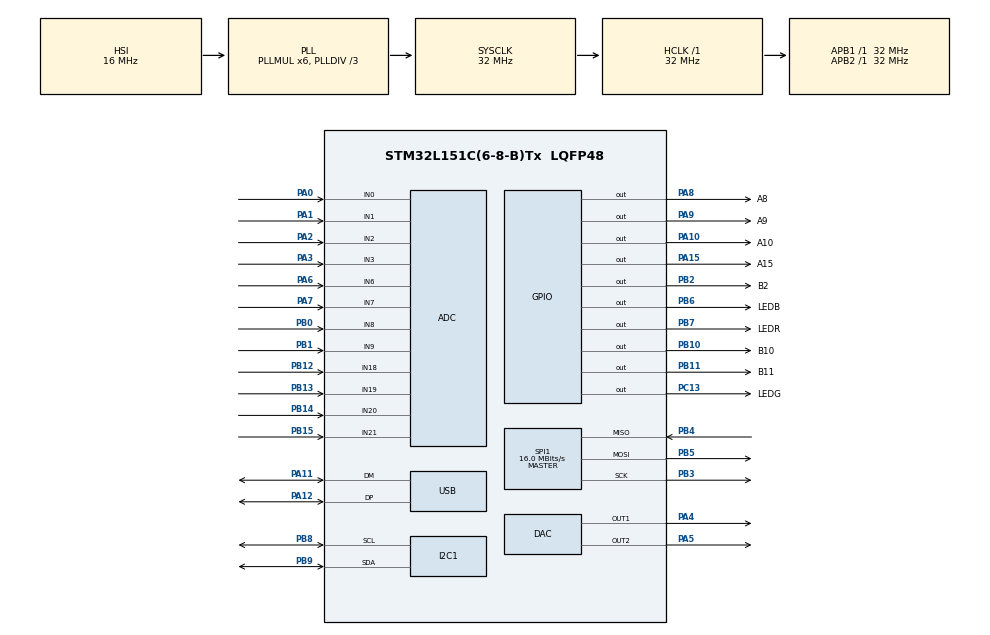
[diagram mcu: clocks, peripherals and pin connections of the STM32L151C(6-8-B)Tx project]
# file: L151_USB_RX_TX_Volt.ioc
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ADC.Channel-0\#ChannelRegularConversion=ADC_CHANNEL_VREFINT
ADC.Channel-1\#ChannelRegularConversion=ADC_CHANNEL_TEMPSENSOR
ADC.Channel-10\#ChannelRegularConversion=ADC_CHANNEL_18
ADC.Channel-11\#ChannelRegularConversion=ADC_CHANNEL_19
ADC.Channel-12\#ChannelRegularConversion=ADC_CHANNEL_20
ADC.Channel-13\#ChannelRegularConversion=ADC_CHANNEL_21
ADC.Channel-2\#ChannelRegularConversion=ADC_CHANNEL_0
ADC.Channel-3\#ChannelRegularConversion=ADC_CHANNEL_1
ADC.Channel-4\#ChannelRegularConversion=ADC_CHANNEL_2
ADC.Channel-5\#ChannelRegularConversion=ADC_CHANNEL_3
ADC.Channel-6\#ChannelRegularConversion=ADC_CHANNEL_6
ADC.Channel-7\#ChannelRegularConversion=ADC_CHANNEL_7
ADC.Channel-8\#ChannelRegularConversion=ADC_CHANNEL_8
ADC.Channel-9\#ChannelRegularConversion=ADC_CHANNEL_9
ADC.ClockPrescaler=ADC_CLOCK_ASYNC_DIV4
ADC.ContinuousConvMode=ENABLE
ADC.DMAContinuousRequests=ENABLE
ADC.NbrOfConversion=14
ADC.NbrOfConversionFlag=1
ADC.Rank-0\#ChannelRegularConversion=1
ADC.Rank-1\#ChannelRegularConversion=2
ADC.Rank-10\#ChannelRegularConversion=11
ADC.Rank-11\#ChannelRegularConversion=12
ADC.Rank-12\#ChannelRegularConversion=13
ADC.Rank-13\#ChannelRegularConversion=14
ADC.Rank-2\#ChannelRegularConversion=3
ADC.Rank-3\#ChannelRegularConversion=4
ADC.Rank-4\#ChannelRegularConversion=5
ADC.Rank-5\#ChannelRegularConversion=6
ADC.Rank-6\#ChannelRegularConversion=7
ADC.Rank-7\#ChannelRegularConversion=8
ADC.Rank-8\#ChannelRegularConversion=9
ADC.Rank-9\#ChannelRegularConversion=10
ADC.SamplingTime-0\#ChannelRegularConversion=ADC_SAMPLETIME_384CYCLES
ADC.SamplingTime-1\#ChannelRegularConversion=ADC_SAMPLETIME_384CYCLES
ADC.SamplingTime-10\#ChannelRegularConversion=ADC_SAMPLETIME_384CYCLES
ADC.SamplingTime-11\#ChannelRegularConversion=ADC_SAMPLETIME_384CYCLES
ADC.SamplingTime-12\#ChannelRegularConversion=ADC_SAMPLETIME_384CYCLES
ADC.SamplingTime-13\#ChannelRegularConversion=ADC_SAMPLETIME_384CYCLES
ADC.SamplingTime-2\#ChannelRegularConversion=ADC_SAMPLETIME_384CYCLES
ADC.SamplingTime-3\#ChannelRegularConversion=ADC_SAMPLETIME_384CYCLES
ADC.SamplingTime-4\#ChannelRegularConversion=ADC_SAMPLETIME_384CYCLES
ADC.SamplingTime-5\#ChannelRegularConversion=ADC_SAMPLETIME_384CYCLES
ADC.SamplingTime-6\#ChannelRegularConversion=ADC_SAMPLETIME_384CYCLES
ADC.SamplingTime-7\#ChannelRegularConversion=ADC_SAMPLETIME_384CYCLES
ADC.SamplingTime-8\#ChannelRegularConversion=ADC_SAMPLETIME_384CYCLES
ADC.SamplingTime-9\#ChannelRegularConversion=ADC_SAMPLETIME_384CYCLES
ADC.ScanConvMode=ADC_SCAN_ENABLE
Dma.ADC.0.Direction=DMA_PERIPH_TO_MEMORY
Dma.ADC.0.Instance=DMA1_Channel1
Dma.ADC.0.MemDataAlignment=DMA_MDATAALIGN_HALFWORD
Dma.ADC.0.MemInc=DMA_MINC_ENABLE
Dma.ADC.0.Mode=DMA_CIRCULAR
Dma.ADC.0.PeriphDataAlignment=DMA_PDATAALIGN_HALFWORD
Dma.ADC.0.PeriphInc=DMA_PINC_DISABLE
Dma.ADC.0.Priority=DMA_PRIORITY_LOW
Dma.Request0=ADC
Mcu.Family=STM32L1
Mcu.Name=STM32L151C(6-8-B)Tx
Mcu.Package=LQFP48
NVIC.DMA1_Channel1_IRQn=true\:0\:0\:false\:false\:true\:false\:true\:true
NVIC.PriorityGroup=NVIC_PRIORITYGROUP_4
NVIC.USB_LP_IRQn=true\:0\:0\:false\:false\:true\:false\:true\:true
PA0-WKUP1.Mode=IN0
PA0-WKUP1.Signal=ADC_IN0
PA1.Mode=IN1
PA1.Signal=ADC_IN1
PA10.GPIO_Label=A10
PA10.Signal=GPIO_Output
PA11.Mode=Device
PA11.Signal=USB_DM
PA12.Mode=Device
PA12.Signal=USB_DP
PA13.Mode=Serial_Wire
PA13.Signal=SYS_JTMS-SWDIO
PA14.Mode=Serial_Wire
PA14.Signal=SYS_JTCK-SWCLK
PA15.GPIO_Label=A15
PA15.Signal=GPIO_Output
PA2.Mode=IN2
PA2.Signal=ADC_IN2
PA3.Mode=IN3
PA3.Signal=ADC_IN3
PA4.Signal=COMP_DAC1_group
PA5.Signal=COMP_DAC2_group
PA6.Mode=IN6
PA6.Signal=ADC_IN6
PA7.Mode=IN7
PA7.Signal=ADC_IN7
PA8.GPIO_Label=A8
PA8.Signal=GPIO_Output
PA9.GPIO_Label=A9
PA9.Signal=GPIO_Output
PB0.Mode=IN8
PB0.Signal=ADC_IN8
PB1.Mode=IN9
PB1.Signal=ADC_IN9
PB10.GPIO_Label=B10
PB10.Signal=GPIO_Output
PB11.GPIO_Label=B11
PB11.Signal=GPIO_Output
PB12.Mode=IN18
PB12.Signal=ADC_IN18
PB13.Mode=IN19
PB13.Signal=ADC_IN19
PB14.Mode=IN20
PB14.Signal=ADC_IN20
PB15.Mode=IN21
PB15.Signal=ADC_IN21
PB2.GPIO_Label=B2
PB2.Signal=GPIO_Output
PB3.Mode=Full_Duplex_Master
PB3.Signal=SPI1_SCK
PB4.Mode=Full_Duplex_Master
PB4.Signal=SPI1_MISO
PB5.Mode=Full_Duplex_Master
PB5.Signal=SPI1_MOSI
PB6.GPIO_Label=LEDB
PB6.Signal=GPIO_Output
PB7.GPIO_Label=LEDR
PB7.Signal=GPIO_Output
PB8.Mode=I2C
PB8.Signal=I2C1_SCL
PB9.Mode=I2C
PB9.Signal=I2C1_SDA
PC13-WKUP2.GPIO_Label=LEDG
PC13-WKUP2.Signal=GPIO_Output
ProjectManager.HeapSize=0x200
ProjectManager.StackSize=0x400
ProjectManager.TargetToolchain=STM32CubeIDE
RCC.48MHZClocksFreq_Value=48000000
RCC.AHBFreq_Value=32000000
RCC.APB1Freq_Value=32000000
RCC.APB1TimFreq_Value=32000000
RCC.APB2Freq_Value=32000000
RCC.APB2TimFreq_Value=32000000
RCC.HCLKFreq_Value=32000000
RCC.HSE_VALUE=12000000
RCC.HSI_VALUE=16000000
RCC.LSE_VALUE=32768
RCC.MSI_VALUE=2097000
RCC.PLLDIV=RCC_PLL_DIV3
RCC.PLLMUL=RCC_PLL_MUL6
RCC.PLLSource=RCC_PLLSOURCE_HSI
RCC.PLLSourceVirtualString=RCC_PLLSOURCE_HSI
RCC.SYSCLKFreq_VALUE=32000000
RCC.SYSCLKSource=RCC_SYSCLKSOURCE_PLLCLK
RCC.VCOOutputFreq_Value=96000000
SH.COMP_DAC1_group.0=DAC_OUT1,DAC_OUT1
SH.COMP_DAC2_group.0=DAC_OUT2,DAC_OUT2
SPI1.CalculateBaudRate=16.0 MBits/s
SPI1.Direction=SPI_DIRECTION_2LINES
SPI1.Mode=SPI_MODE_MASTER
SPI1.VirtualType=VM_MASTER
USB_DEVICE.CLASS_NAME_FS=CDC
USB_DEVICE.VirtualMode=Cdc
USB_DEVICE.VirtualModeFS=Cdc_FS
VP_ADC_TempSens_Input.Mode=IN-TempSens
VP_ADC_Vref_Input.Mode=IN-Vrefint
VP_USB_DEVICE_VS_USB_DEVICE_CDC_FS.Mode=CDC_FS
board=custom

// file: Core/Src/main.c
/* USER CODE BEGIN Header */
/**
  ******************************************************************************
  * @file           : main.c
  * @brief          : Main program body
  ******************************************************************************
  * @attention
  *
  * Copyright (c) 2023 STMicroelectronics.
  * All rights reserved.
  *
  * This software is licensed under terms that can be found in the LICENSE file
  * in the root directory of this software component.
  * If no LICENSE file comes with this software, it is provided AS-IS.
  *
  ******************************************************************************
  */
/* USER CODE END Header */
#include "main.h"
#include "adc.h"
#include "dac.h"
#include "dma.h"
#include "i2c.h"
#include "spi.h"
#include "usb_device.h"
#include "gpio.h"

/* USER CODE BEGIN Includes */
#include "kernel.h"
/* USER CODE END Includes */

void SystemClock_Config(void);

int main(void)
{

  /* MCU Configuration--------------------------------------------------------*/

  /* Reset of all peripherals, Initializes the Flash interface and the Systick. */
  HAL_Init();

  /* Configure the system clock */
  SystemClock_Config();

  /* Initialize all configured peripherals */
  MX_GPIO_Init();
  MX_DMA_Init();
  MX_ADC_Init();
  MX_USB_DEVICE_Init();
  MX_DAC_Init();
  MX_I2C1_Init();
  MX_SPI1_Init();

  /* Infinite loop */
  /* USER CODE BEGIN WHILE */
  while (1)
  {
	  kernel_main();
    /* USER CODE END WHILE */

  }
}

void SystemClock_Config(void)
{
  RCC_OscInitTypeDef RCC_OscInitStruct = {0};
  RCC_ClkInitTypeDef RCC_ClkInitStruct = {0};

  /** Configure the main internal regulator output voltage
  */
  __HAL_PWR_VOLTAGESCALING_CONFIG(PWR_REGULATOR_VOLTAGE_SCALE1);

  /** Initializes the RCC Oscillators according to the specified parameters
  * in the RCC_OscInitTypeDef structure.
  */
  RCC_OscInitStruct.OscillatorType = RCC_OSCILLATORTYPE_HSI;
  RCC_OscInitStruct.HSIState = RCC_HSI_ON;
  RCC_OscInitStruct.HSICalibrationValue = RCC_HSICALIBRATION_DEFAULT;
  RCC_OscInitStruct.PLL.PLLState = RCC_PLL_ON;
  RCC_OscInitStruct.PLL.PLLSource = RCC_PLLSOURCE_HSI;
  RCC_OscInitStruct.PLL.PLLMUL = RCC_PLL_MUL6;
  RCC_OscInitStruct.PLL.PLLDIV = RCC_PLL_DIV3;
  if (HAL_RCC_OscConfig(&RCC_OscInitStruct) != HAL_OK)
  {
    Error_Handler();
  }

  /** Initializes the CPU, AHB and APB buses clocks
  */
  RCC_ClkInitStruct.ClockType = RCC_CLOCKTYPE_HCLK|RCC_CLOCKTYPE_SYSCLK
                              |RCC_CLOCKTYPE_PCLK1|RCC_CLOCKTYPE_PCLK2;
  RCC_ClkInitStruct.SYSCLKSource = RCC_SYSCLKSOURCE_PLLCLK;
  RCC_ClkInitStruct.AHBCLKDivider = RCC_SYSCLK_DIV1;
  RCC_ClkInitStruct.APB1CLKDivider = RCC_HCLK_DIV1;
  RCC_ClkInitStruct.APB2CLKDivider = RCC_HCLK_DIV1;

  if (HAL_RCC_ClockConfig(&RCC_ClkInitStruct, FLASH_LATENCY_1) != HAL_OK)
  {
    Error_Handler();
  }
}

void Error_Handler(void)
{
  __disable_irq();
  while (1)
  {
  }
}
